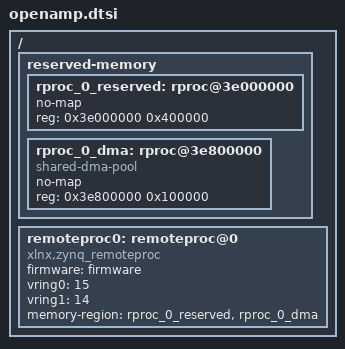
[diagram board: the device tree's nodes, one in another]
/ {
	reserved-memory {
		#address-cells = <1>;
		#size-cells = <1>;
		ranges;
		rproc_0_reserved: rproc@3e000000 {
			no-map;
			reg = <0x3e000000 0x400000>;
		};
		rproc_0_dma: rproc@3e800000 {
			no-map;
			compatible = "shared-dma-pool";
			reg = <0x3e800000 0x100000>;
		};
	};

	remoteproc0: remoteproc@0 {
		compatible = "xlnx,zynq_remoteproc";
		firmware = "firmware";
		vring0 = <15>;
		vring1 = <14>;
		memory-region = <&rproc_0_reserved>, <&rproc_0_dma>;
	};
};
